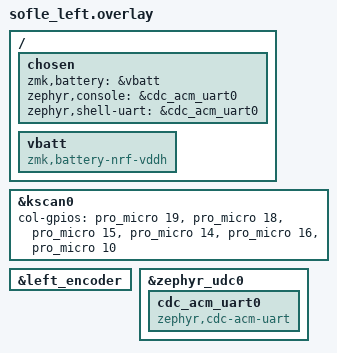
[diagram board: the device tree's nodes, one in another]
/*
 * Copyright (c) 2020 Ryan Cross
 *
 * SPDX-License-Identifier: MIT
 */

#include "sofle.dtsi"

&kscan0 {
    col-gpios
        = <&pro_micro 19 GPIO_ACTIVE_HIGH>
        , <&pro_micro 18 GPIO_ACTIVE_HIGH>
        , <&pro_micro 15 GPIO_ACTIVE_HIGH>
        , <&pro_micro 14 GPIO_ACTIVE_HIGH>
        , <&pro_micro 16 GPIO_ACTIVE_HIGH>
        , <&pro_micro 10 GPIO_ACTIVE_HIGH>
        ;
};

&left_encoder {
    status = "okay";
};
/ {
    chosen {
      zmk,battery = &vbatt;
    };

    vbatt: vbatt {
        compatible = "zmk,battery-nrf-vddh";
    };

    /* diag: console for CONFIG_ZMK_USB_LOGGING (CDC ACM next to USB HID) */
    chosen {
        zephyr,console = &cdc_acm_uart0;
        zephyr,shell-uart = &cdc_acm_uart0;
    };
};

&zephyr_udc0 {
    cdc_acm_uart0: cdc_acm_uart0 {
        compatible = "zephyr,cdc-acm-uart";
    };
};
